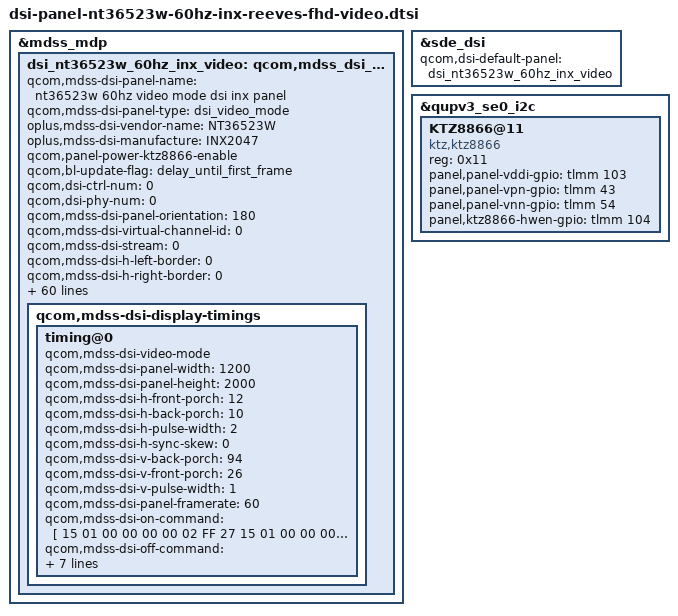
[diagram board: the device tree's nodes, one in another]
&mdss_mdp {
	dsi_nt36523w_60hz_inx_video: qcom,mdss_dsi_nt36523w_60hz_inx_video {
		qcom,mdss-dsi-panel-name =
			"nt36523w 60hz video mode dsi inx panel";
		qcom,mdss-dsi-panel-type = "dsi_video_mode";
		oplus,mdss-dsi-vendor-name = "NT36523W";
		oplus,mdss-dsi-manufacture = "INX2047";
		qcom,panel-power-ktz8866-enable;
		qcom,bl-update-flag = "delay_until_first_frame";

		qcom,dsi-ctrl-num = <0>;
		qcom,dsi-phy-num = <0>;
		qcom,mdss-dsi-panel-orientation = "180";
		qcom,mdss-dsi-virtual-channel-id = <0>;
		qcom,mdss-dsi-stream = <0>;
		qcom,mdss-dsi-h-left-border = <0>;
		qcom,mdss-dsi-h-right-border = <0>;
		qcom,mdss-dsi-v-top-border = <0>;
		qcom,mdss-dsi-v-bottom-border = <0>;
		qcom,mdss-dsi-bpp = <24>;
		qcom,mdss-dsi-color-order = "rgb_swap_rgb";
		qcom,mdss-dsi-underflow-color = <0xff>;
		qcom,mdss-dsi-border-color = <0>;
		qcom,mdss-dsi-h-sync-pulse = <0>;
		qcom,mdss-dsi-traffic-mode = "non_burst_sync_event";
		qcom,mdss-dsi-lane-map = "lane_map_0123";
		qcom,mdss-dsi-bllp-eof-power-mode;
		qcom,mdss-dsi-bllp-power-mode;
		qcom,mdss-dsi-tx-eot-append;
		qcom,mdss-dsi-lane-0-state;
		qcom,mdss-dsi-lane-1-state;
		qcom,mdss-dsi-lane-2-state;
		qcom,mdss-dsi-lane-3-state;
		qcom,mdss-dsi-dma-trigger = "trigger_sw";
		qcom,mdss-dsi-mdp-trigger = "none";
		qcom,mdss-dsi-lp11-init;
		qcom,mdss-dsi-incell-screen;
		qcom,mdss-dsi-bl-pmic-control-type = "bl_ctrl_external";
		qcom,mdss-dsi-reset-sequence = <0 10>, <1 10>, <0 10>, <1 10>;
		qcom,mdss-pan-physical-width-dimension = <135>;
		qcom,mdss-pan-physical-height-dimension = <226>;
		qcom,mdss-dsi-display-timings {
			timing@0 {
				qcom,mdss-dsi-video-mode;
				qcom,mdss-dsi-panel-width = <1200>;
				qcom,mdss-dsi-panel-height = <2000>;
				qcom,mdss-dsi-h-front-porch = <12>;
				qcom,mdss-dsi-h-back-porch = <10>;
				qcom,mdss-dsi-h-pulse-width = <2>;
				qcom,mdss-dsi-h-sync-skew = <0>;
				qcom,mdss-dsi-v-back-porch = <94>;
				qcom,mdss-dsi-v-front-porch = <26>;
				qcom,mdss-dsi-v-pulse-width = <1>;
				qcom,mdss-dsi-panel-framerate = <60>;
				qcom,mdss-dsi-on-command = [
					15 01 00 00 00 00 02 FF 27
					15 01 00 00 00 00 02 FB 01
					15 01 00 00 00 00 02 D0 31
					15 01 00 00 00 00 02 D1 88
					15 01 00 00 00 00 02 D2 30
					15 01 00 00 00 00 02 DE 43
					15 01 00 00 00 00 02 DF 02
					15 01 00 00 00 00 02 FF D0
					15 01 00 00 00 00 02 FB 01
					15 01 00 00 00 00 02 00 02
					15 01 00 00 00 00 02 FF 20
					15 01 00 00 00 00 02 FB 01
					15 01 00 00 00 00 02 05 D9
					15 01 00 00 00 00 02 0D 63
					15 01 00 00 00 00 02 0E 91
					15 01 00 00 00 00 02 0F 69
					15 01 00 00 00 00 02 07 7D
					15 01 00 00 00 00 02 08 5F
					15 01 00 00 00 00 02 0E 7D
					15 01 00 00 00 00 02 0F 7D
					15 01 00 00 00 00 02 95 F5
					15 01 00 00 00 00 02 96 F5
					15 01 00 00 00 00 02 9D 00
					15 01 00 00 00 00 02 9E 00
					15 01 00 00 00 00 02 44 51
					15 01 00 00 00 00 02 FF 20
					15 01 00 00 00 00 02 FB 01
					39 01 00 00 00 00 11 B0 00 00 00 1d 00 41 00 60 00 7a 00 91 00 a5 00 b8
					39 01 00 00 00 00 11 B1 00 c8 01 00 01 2a 01 6c 01 9f 01 ec 02 2b 02 2d
					39 01 00 00 00 00 11 B2 02 68 02 a9 02 d2 03 06 03 2a 03 53 03 5d 03 64
					39 01 00 00 00 00 0D B3 03 6a 03 76 03 80 03 8a 03 96 03 9a
					39 01 00 00 00 00 11 B4 00 00 00 1d 00 41 00 60 00 7a 00 91 00 a5 00 b8
					39 01 00 00 00 00 11 B5 00 c8 01 00 01 2a 01 6c 01 9f 01 ec 02 2b 02 2d
					39 01 00 00 00 00 11 B6 02 68 02 a9 02 d2 03 06 03 2a 03 53 03 5d 03 64
					39 01 00 00 00 00 0D B7 03 6a 03 76 03 80 03 8a 03 96 03 9a
					39 01 00 00 00 00 11 B8 00 00 00 1d 00 41 00 60 00 7a 00 91 00 a5 00 b8
					39 01 00 00 00 00 11 B9 00 c8 01 00 01 2a 01 6c 01 9f 01 ec 02 2b 02 2d
					39 01 00 00 00 00 11 BA 02 68 02 a9 02 d2 03 06 03 2a 03 53 03 5d 03 64
					39 01 00 00 00 00 0D BB 03 6a 03 76 03 80 03 8a 03 96 03 9a
					15 01 00 00 00 00 02 FF 21
					15 01 00 00 00 00 02 FB 01
					39 01 00 00 00 00 11 B0 00 00 00 1d 00 41 00 60 00 7a 00 91 00 a5 00 b8
					39 01 00 00 00 00 11 B1 00 c8 01 00 01 2a 01 6c 01 9f 01 ec 02 2b 02 2d
					39 01 00 00 00 00 11 B2 02 68 02 a9 02 d2 03 06 03 2a 03 53 03 61 03 74
					39 01 00 00 00 00 0D B3 03 8c 03 a3 03 c8 03 de 03 e6 03 e6
					39 01 00 00 00 00 11 B4 00 00 00 1d 00 41 00 60 00 7a 00 91 00 a5 00 b8
					39 01 00 00 00 00 11 B5 00 c8 01 00 01 2a 01 6c 01 9f 01 ec 02 2b 02 2d
					39 01 00 00 00 00 11 B6 02 68 02 a9 02 d2 03 06 03 2a 03 53 03 61 03 74
					39 01 00 00 00 00 0D B7 03 8c 03 a3 03 c8 03 de 03 e6 03 e6
					39 01 00 00 00 00 11 B8 00 00 00 1d 00 41 00 60 00 7a 00 91 00 a5 00 b8
					39 01 00 00 00 00 11 B9 00 c8 01 00 01 2a 01 6c 01 9f 01 ec 02 2b 02 2d
					39 01 00 00 00 00 11 BA 02 68 02 a9 02 d2 03 06 03 2a 03 53 03 61 03 74
					39 01 00 00 00 00 0D BB 03 8c 03 a3 03 c8 03 de 03 e6 03 e6
					15 01 00 00 00 00 02 FF 24
					15 01 00 00 00 00 02 FB 01
					15 01 00 00 00 00 02 91 44
					15 01 00 00 00 00 02 92 77
					15 01 00 00 00 00 02 93 1A
					15 01 00 00 00 00 02 94 40
					15 01 00 00 00 00 02 9A 08
					15 01 00 00 00 00 02 60 96
					15 01 00 00 00 00 02 61 D0
					15 01 00 00 00 00 02 63 70
					15 01 00 00 00 00 02 C2 C6
					15 01 00 00 00 00 02 9B 0F
					15 01 00 00 00 00 02 9A 08
					15 01 00 00 00 00 02 A5 00
					15 01 00 00 00 00 02 A6 41
					15 01 00 00 00 00 02 00 03
					15 01 00 00 00 00 02 01 03
					15 01 00 00 00 00 02 02 03
					15 01 00 00 00 00 02 03 03
					15 01 00 00 00 00 02 04 03
					15 01 00 00 00 00 02 05 03
					15 01 00 00 00 00 02 06 03
					15 01 00 00 00 00 02 07 03
					15 01 00 00 00 00 02 08 22
					15 01 00 00 00 00 02 09 08
					15 01 00 00 00 00 02 0A 05
					15 01 00 00 00 00 02 0B 1D
					15 01 00 00 00 00 02 0C 1C
					15 01 00 00 00 00 02 0D 11
					15 01 00 00 00 00 02 0E 10
					15 01 00 00 00 00 02 0F 0F
					15 01 00 00 00 00 02 10 0E
					15 01 00 00 00 00 02 11 0D
					15 01 00 00 00 00 02 12 0C
					15 01 00 00 00 00 02 13 04
					15 01 00 00 00 00 02 14 03
					15 01 00 00 00 00 02 15 03
					15 01 00 00 00 00 02 16 03
					15 01 00 00 00 00 02 17 03
					15 01 00 00 00 00 02 18 03
					15 01 00 00 00 00 02 19 03
					15 01 00 00 00 00 02 1A 03
					15 01 00 00 00 00 02 1B 03
					15 01 00 00 00 00 02 1C 03
					15 01 00 00 00 00 02 1D 03
					15 01 00 00 00 00 02 1E 22
					15 01 00 00 00 00 02 1F 08
					15 01 00 00 00 00 02 20 05
					15 01 00 00 00 00 02 21 1D
					15 01 00 00 00 00 02 22 1C
					15 01 00 00 00 00 02 23 11
					15 01 00 00 00 00 02 24 10
					15 01 00 00 00 00 02 25 0F
					15 01 00 00 00 00 02 26 0E
					15 01 00 00 00 00 02 27 0D
					15 01 00 00 00 00 02 28 0C
					15 01 00 00 00 00 02 29 04
					15 01 00 00 00 00 02 2A 03
					15 01 00 00 00 00 02 2B 03
					15 01 00 00 00 00 02 2F 05
					15 01 00 00 00 00 02 30 33
					15 01 00 00 00 00 02 31 40
					15 01 00 00 00 00 02 33 33
					15 01 00 00 00 00 02 34 05
					15 01 00 00 00 00 02 35 40
					15 01 00 00 00 00 02 37 55
					15 01 00 00 00 00 02 38 40
					15 01 00 00 00 00 02 39 00
					15 01 00 00 00 00 02 3A 51
					15 01 00 00 00 00 02 3B 3E
					15 01 00 00 00 00 02 3D 92
					15 01 00 00 00 00 02 AB 55
					15 01 00 00 00 00 02 AC 40
					15 01 00 00 00 00 02 3F 40
					15 01 00 00 00 00 02 43 40
					15 01 00 00 00 00 02 47 55
					15 01 00 00 00 00 02 4A 51
					15 01 00 00 00 00 02 4B 3E
					15 01 00 00 00 00 02 4C 91
					15 01 00 00 00 00 02 4D 21
					15 01 00 00 00 00 02 4E 43
					15 01 00 00 00 00 02 4F 65
					15 01 00 00 00 00 02 51 34
					15 01 00 00 00 00 02 52 12
					15 01 00 00 00 00 02 53 56
					39 01 00 00 00 00 03 55 84 04
					15 01 00 00 00 00 02 56 06
					15 01 00 00 00 00 02 58 21
					15 01 00 00 00 00 02 59 50
					15 01 00 00 00 00 02 5A 51
					15 01 00 00 00 00 02 5B 3E
					39 01 00 00 00 00 03 5E 00 0C
					15 01 00 00 00 00 02 5F 00
					15 01 00 00 00 00 02 7A FF
					15 01 00 00 00 00 02 7B FF
					15 01 00 00 00 00 02 7C 00
					15 01 00 00 00 00 02 7D 00
					15 01 00 00 00 00 02 7E 20
					15 01 00 00 00 00 02 7F 3C
					15 01 00 00 00 00 02 80 00
					15 01 00 00 00 00 02 81 00
					15 01 00 00 00 00 02 82 08
					15 01 00 00 00 00 02 97 02
					15 01 00 00 00 00 02 C5 10
					15 01 00 00 00 00 02 D7 55
					15 01 00 00 00 00 02 D8 55
					15 01 00 00 00 00 02 D9 23
					15 01 00 00 00 00 02 DA 05
					15 01 00 00 00 00 02 DB 01
					15 01 00 00 00 00 02 DC 77
					15 01 00 00 00 00 02 DD 55
					15 01 00 00 00 00 02 DE 27
					15 01 00 00 00 00 02 DF 01
					15 01 00 00 00 00 02 E0 77
					15 01 00 00 00 00 02 E1 01
					15 01 00 00 00 00 02 E2 77
					15 01 00 00 00 00 02 E3 01
					15 01 00 00 00 00 02 E4 77
					15 01 00 00 00 00 02 E5 01
					15 01 00 00 00 00 02 E6 77
					15 01 00 00 00 00 02 E7 00
					15 01 00 00 00 00 02 E8 00
					15 01 00 00 00 00 02 E9 01
					15 01 00 00 00 00 02 EA 77
					15 01 00 00 00 00 02 EB 01
					15 01 00 00 00 00 02 EE 77
					15 01 00 00 00 00 02 EF 01
					15 01 00 00 00 00 02 F0 77
					15 01 00 00 00 00 02 FF 25
					15 01 00 00 00 00 02 FB 01
					15 01 00 00 00 00 02 05 00
					15 01 00 00 00 00 02 F1 10
					15 01 00 00 00 00 02 1E 00
					15 01 00 00 00 00 02 1F 51
					15 01 00 00 00 00 02 20 3E
					15 01 00 00 00 00 02 25 00
					15 01 00 00 00 00 02 26 51
					15 01 00 00 00 00 02 27 3E
					15 01 00 00 00 00 02 3F 80
					15 01 00 00 00 00 02 40 00
					15 01 00 00 00 00 02 43 00
					15 01 00 00 00 00 02 44 51
					15 01 00 00 00 00 02 45 3E
					15 01 00 00 00 00 02 48 51
					15 01 00 00 00 00 02 49 3E
					15 01 00 00 00 00 02 5B 80
					15 01 00 00 00 00 02 5C 00
					15 01 00 00 00 00 02 5D 51
					15 01 00 00 00 00 02 5E 3E
					15 01 00 00 00 00 02 5F 51
					15 01 00 00 00 00 02 60 3E
					15 01 00 00 00 00 02 61 51
					15 01 00 00 00 00 02 62 3E
					15 01 00 00 00 00 02 68 0C
					15 01 00 00 00 00 02 FF 26
					15 01 00 00 00 00 02 FB 01
					15 01 00 00 00 00 02 00 A1
					15 01 00 00 00 00 02 02 31
					15 01 00 00 00 00 02 04 28
					15 01 00 00 00 00 02 06 30
					15 01 00 00 00 00 02 0C 13
					15 01 00 00 00 00 02 0D 0A
					15 01 00 00 00 00 02 0F 0A
					15 01 00 00 00 00 02 11 00
					15 01 00 00 00 00 02 12 50
					15 01 00 00 00 00 02 13 51
					15 01 00 00 00 00 02 14 65
					15 01 00 00 00 00 02 15 00
					15 01 00 00 00 00 02 16 10
					15 01 00 00 00 00 02 17 A0
					15 01 00 00 00 00 02 18 86
					15 01 00 00 00 00 02 22 00
					15 01 00 00 00 00 02 23 00
					15 01 00 00 00 00 02 19 0A
					15 01 00 00 00 00 02 1A A0
					15 01 00 00 00 00 02 1B 0A
					15 01 00 00 00 00 02 1C 00
					15 01 00 00 00 00 02 2A 0A
					15 01 00 00 00 00 02 2B A0
					15 01 00 00 00 00 02 1D 00
					15 01 00 00 00 00 02 1E 77
					15 01 00 00 00 00 02 1F 77
					15 01 00 00 00 00 02 2F 04
					15 01 00 00 00 00 02 30 77
					15 01 00 00 00 00 02 31 04
					15 01 00 00 00 00 02 32 97
					15 01 00 00 00 00 02 33 89
					15 01 00 00 00 00 02 34 67
					15 01 00 00 00 00 02 39 0C
					15 01 00 00 00 00 02 3A 74
					15 01 00 00 00 00 02 3B 06
					15 01 00 00 00 00 02 C8 04
					15 01 00 00 00 00 02 C9 8B
					15 01 00 00 00 00 02 CA 4E
					15 01 00 00 00 00 02 CB 00
					15 01 00 00 00 00 02 A9 50
					15 01 00 00 00 00 02 AA 4F
					15 01 00 00 00 00 02 AB 4E
					15 01 00 00 00 00 02 AC 4D
					15 01 00 00 00 00 02 AD 4C
					15 01 00 00 00 00 02 AE 4B
					15 01 00 00 00 00 02 AF 4A
					15 01 00 00 00 00 02 B0 49
					15 01 00 00 00 00 02 B1 47
					15 01 00 00 00 00 02 B2 45
					15 01 00 00 00 00 02 FF 27
					15 01 00 00 00 00 02 C0 18
					15 01 00 00 00 00 02 C1 00
					15 01 00 00 00 00 02 C2 00
					15 01 00 00 00 00 02 56 06
					15 01 00 00 00 00 02 58 80
					15 01 00 00 00 00 02 59 52
					15 01 00 00 00 00 02 5A 00
					15 01 00 00 00 00 02 5B 14
					15 01 00 00 00 00 02 5C 00
					15 01 00 00 00 00 02 5D 00
					15 01 00 00 00 00 02 5E 20
					15 01 00 00 00 00 02 5F 10
					15 01 00 00 00 00 02 60 00
					15 01 00 00 00 00 02 61 1B
					15 01 00 00 00 00 02 62 00
					15 01 00 00 00 00 02 63 01
					15 01 00 00 00 00 02 64 23
					15 01 00 00 00 00 02 65 1A
					15 01 00 00 00 00 02 66 00
					15 01 00 00 00 00 02 67 01
					15 01 00 00 00 00 02 68 23
					15 01 00 00 00 00 02 00 00
					15 01 00 00 00 00 02 C3 00
					15 01 00 00 00 00 02 98 01
					15 01 00 00 00 00 02 B4 03
					15 01 00 00 00 00 02 9B BE
					15 01 00 00 00 00 02 AB 14
					15 01 00 00 00 00 02 BC 08
					15 01 00 00 00 00 02 BD 28
					15 01 00 00 00 00 02 FF 2A
					15 01 00 00 00 00 02 FB 01
					15 01 00 00 00 00 02 22 2F
					15 01 00 00 00 00 02 23 08
					15 01 00 00 00 00 02 24 00
					15 01 00 00 00 00 02 25 76
					15 01 00 00 00 00 02 26 F8
					15 01 00 00 00 00 02 27 00
					15 01 00 00 00 00 02 28 1A
					15 01 00 00 00 00 02 29 00
					15 01 00 00 00 00 02 2A 1A
					15 01 00 00 00 00 02 2B 00
					15 01 00 00 00 00 02 2D 1A
					15 01 00 00 00 00 02 64 96
					15 01 00 00 00 00 02 65 00
					15 01 00 00 00 00 02 66 00
					15 01 00 00 00 00 02 6A 96
					15 01 00 00 00 00 02 6B 00
					15 01 00 00 00 00 02 6C 00
					15 01 00 00 00 00 02 70 92
					15 01 00 00 00 00 02 71 00
					15 01 00 00 00 00 02 72 00
					15 01 00 00 00 00 02 A2 33
					15 01 00 00 00 00 02 A3 30
					15 01 00 00 00 00 02 A4 C0
					15 01 00 00 00 00 02 E8 00
					15 01 00 00 00 00 02 97 3C
					15 01 00 00 00 00 02 98 02
					15 01 00 00 00 00 02 99 95
					15 01 00 00 00 00 02 9A 06
					15 01 00 00 00 00 02 9B 00
					15 01 00 00 00 00 02 9C 0B
					15 01 00 00 00 00 02 9D 0A
					15 01 00 00 00 00 02 9E 90
					15 01 00 00 00 00 02 FF 25
					15 01 00 00 00 00 02 13 02
					15 01 00 00 00 00 02 14 F2
					15 01 00 00 00 00 02 FF 25
					15 01 00 00 00 00 02 FB 01
					15 01 00 00 00 00 02 17 CF
					15 01 00 00 00 00 02 19 0F
					15 01 00 00 00 00 02 1B 5B
					15 01 00 00 00 00 02 FF 26
					15 01 00 00 00 00 02 FB 01
					15 01 00 00 00 00 02 00 81
					15 01 00 00 00 00 02 01 70
					15 01 00 00 00 00 02 40 76
					15 01 00 00 00 00 02 41 76
					15 01 00 00 00 00 02 42 76
					15 01 00 00 00 00 02 45 04
					15 01 00 00 00 00 02 46 76
					15 01 00 00 00 00 02 47 04
					15 01 00 00 00 00 02 48 83
					15 01 00 00 00 00 02 4D 51
					15 01 00 00 00 00 02 4E 3E
					15 01 00 00 00 00 02 4F 51
					15 01 00 00 00 00 02 50 3E
					15 01 00 00 00 00 02 51 51
					15 01 00 00 00 00 02 52 3E
					15 01 00 00 00 00 02 56 51
					15 01 00 00 00 00 02 58 3E
					15 01 00 00 00 00 02 5B 51
					15 01 00 00 00 00 02 5C 3E
					15 01 00 00 00 00 02 64 51
					15 01 00 00 00 00 02 65 3E
					15 01 00 00 00 00 02 6E 51
					15 01 00 00 00 00 02 6F 3E
					15 01 00 00 00 00 02 70 51
					15 01 00 00 00 00 02 71 3E
					15 01 00 00 00 00 02 72 51
					15 01 00 00 00 00 02 73 3E
					15 01 00 00 00 00 02 8B 50
					15 01 00 00 00 00 02 8C 7C
					15 01 00 00 00 00 02 92 50
					15 01 00 00 00 00 02 93 10
					15 01 00 00 00 00 02 94 10
					15 01 00 00 00 00 02 96 10
					15 01 00 00 00 00 02 C9 80
					15 01 00 00 00 00 02 FF 2A
					15 01 00 00 00 00 02 FB 01
					15 01 00 00 00 00 02 01 01
					15 01 00 00 00 00 02 02 11
					15 01 00 00 00 00 02 05 01
					15 01 00 00 00 00 02 06 76
					15 01 00 00 00 00 02 08 01
					15 01 00 00 00 00 02 09 76
					15 01 00 00 00 00 02 0C 01
					15 01 00 00 00 00 02 0D 76
					15 01 00 00 00 00 02 FF F0
					15 01 00 00 00 00 02 FB 01
					15 01 00 00 00 00 02 3A 08
					15 01 00 00 00 00 02 FF D0
					15 01 00 00 00 00 02 FB 01
					15 01 00 00 00 00 02 02 AF
					15 01 00 00 00 00 02 09 FF
					15 01 00 00 00 00 02 FF 23
					15 01 00 00 00 00 02 FB 01
					15 01 00 00 00 00 02 00 68
					15 01 00 00 00 00 02 07 00
					15 01 00 00 00 00 02 08 01
					15 01 00 00 00 00 02 09 90
					15 01 00 00 00 00 02 FF 23
					15 01 00 00 00 00 02 FB 01
					15 01 00 00 00 00 02 10 0C
					15 01 00 00 00 00 02 11 02
					15 01 00 00 00 00 02 12 80
					15 01 00 00 00 00 02 15 83
					15 01 00 00 00 00 02 16 0C
					15 01 00 00 00 00 02 19 00
					15 01 00 00 00 00 02 1A 04
					15 01 00 00 00 00 02 1B 08
					15 01 00 00 00 00 02 1C 0C
					15 01 00 00 00 00 02 1D 10
					15 01 00 00 00 00 02 1E 14
					15 01 00 00 00 00 02 1F 18
					15 01 00 00 00 00 02 20 1C
					15 01 00 00 00 00 02 21 20
					15 01 00 00 00 00 02 22 24
					15 01 00 00 00 00 02 23 28
					15 01 00 00 00 00 02 24 2C
					15 01 00 00 00 00 02 25 30
					15 01 00 00 00 00 02 26 34
					15 01 00 00 00 00 02 27 38
					15 01 00 00 00 00 02 28 3C
					15 01 00 00 00 00 02 29 20
					15 01 00 00 00 00 02 2A 20
					15 01 00 00 00 00 02 2B 30
					15 01 00 00 00 00 02 30 FF
					15 01 00 00 00 00 02 31 FC
					15 01 00 00 00 00 02 32 FA
					15 01 00 00 00 00 02 33 F4
					15 01 00 00 00 00 02 34 F2
					15 01 00 00 00 00 02 35 F0
					15 01 00 00 00 00 02 36 EF
					15 01 00 00 00 00 02 37 EC
					15 01 00 00 00 00 02 38 EC
					15 01 00 00 00 00 02 39 E9
					15 01 00 00 00 00 02 3A E9
					15 01 00 00 00 00 02 3B E8
					15 01 00 00 00 00 02 3D E7
					15 01 00 00 00 00 02 3F E6
					15 01 00 00 00 00 02 40 E5
					15 01 00 00 00 00 02 41 E3
					15 01 00 00 00 00 02 58 FF
					15 01 00 00 00 00 02 59 FB
					15 01 00 00 00 00 02 5A EE
					15 01 00 00 00 00 02 5B E8
					15 01 00 00 00 00 02 5C E3
					15 01 00 00 00 00 02 5D DE
					15 01 00 00 00 00 02 5E D6
					15 01 00 00 00 00 02 5F D4
					15 01 00 00 00 00 02 60 D2
					15 01 00 00 00 00 02 61 D0
					15 01 00 00 00 00 02 62 CC
					15 01 00 00 00 00 02 63 CC
					15 01 00 00 00 00 02 64 CA
					15 01 00 00 00 00 02 65 C8
					15 01 00 00 00 00 02 66 C4
					15 01 00 00 00 00 02 67 C0
					15 01 00 00 00 00 02 FF 20
					15 01 00 00 00 00 02 FB 01
					39 01 00 00 00 00 0D C3 27 26 1E 20 19 18 17 16 15 13 07 03
					15 01 00 00 00 00 02 FF 10
					15 01 00 00 00 00 02 B9 01
					15 01 00 00 00 00 02 FF 20
					15 01 00 00 00 00 02 18 40
					15 01 00 00 00 00 02 FF 10
					15 01 00 00 00 00 02 B9 02
					15 01 00 00 00 00 02 FF 10
					15 01 00 00 00 00 02 FB 01
					15 01 00 00 00 00 02 B0 01
					15 01 00 00 00 00 02 35 00
					15 01 00 00 00 00 02 55 00
					39 01 00 00 00 00 03 68 05 01
					39 01 00 00 00 00 06 3B 03 5F 1A 04 04
					05 01 00 00 64 00 02 11 00
					05 01 00 00 00 00 02 29 00];
				qcom,mdss-dsi-off-command = [
					05 01 00 00 14 00 02 28 00
					05 01 00 00 78 00 02 10 00];
				qcom,mdss-dsi-on-command-state = "dsi_lp_mode";
				qcom,mdss-dsi-off-command-state = "dsi_hs_mode";
			};
		};
	};
};

&dsi_nt36523w_60hz_inx_video {
	qcom,mdss-dsi-bl-pmic-control-type = "bl_ctrl_external";
	qcom,mdss-dsi-bl-min-level = <1>;
	qcom,mdss-dsi-bl-normal-max-level = <2047>;
	qcom,mdss-dsi-bl-max-level = <2047>;
	qcom,mdss-brightness-max-level = <2047>;
	qcom,mdss-brightness-min-level = <1>;
    qcom,mdss-brightness-normal-max-level = <2047>;
	qcom,mdss-brightness-default-level = <1600>;
	qcom,platform-reset-gpio = <&tlmm 82 0>;

	oplus,oplus-panel-power-ctl;
	oplus,panel-shutdown-power-set-flag;
	/* close TP gesture sequence */
	oplus,panel-on-power-sequence = "set_bias", "set_reset", "tp_load_fw", "set_end";
	oplus,panel-off-power-sequence = "set_bias", "set_reset_sel", "set_end";
	oplus,panel-shutdown-power-sequence = "set_reset", "set_bias", "set_end";
	/* open TP gesture sequence */
	oplus,panel-gesture-on-power-sequence = "set_bias", "set_reset", "tp_load_fw", "set_end";
	oplus,panel-gesture-off-power-sequence = "set_reset_sel", "set_end";
	oplus,panel-gesture-shutdown-power-sequence = "set_reset", "set_bias", "set_end";
	/* mdelay:<on_behind_mdelay off_behind_mdelay gesture_on_behind_mdelay gesture_off_behind_mdelay> */
	oplus,panel-power-reset-mdelay = <0 3 0 3>;
	oplus,panel-power-regulator-mdelay = <0 70 0 0>;
	oplus,panel-power-pinctrl-mdelay = <0 0 0 70>;
	oplus,panel-on-mdelay-bl = <30>;
};

&dsi_nt36523w_60hz_inx_video {
	qcom,esd-check-enabled;
	qcom,mdss-dsi-panel-status-check-mode = "check_esd_gpio";
	qcom,panel-master-esd-gpio = <&tlmm 81 0>;
	qcom,panel-slaves-esd-gpio = <&tlmm 97 0>;
	qcom,dsi-select-clocks = "mux_byte_clk0", "mux_pixel_clk0";
	qcom,mdss-dsi-display-timings {
		timing@0 {
			qcom,mdss-dsi-panel-phy-timings = [00 20 08 08 18 23 08
					08 08 02 04 00 1B 0D];
			qcom,display-topology = <1 0 1>;
			qcom,default-topology-index = <0>;
		};
	};
};

&sde_dsi {
	qcom,dsi-default-panel = <&dsi_nt36523w_60hz_inx_video>;
};

&qupv3_se0_i2c {
	KTZ8866@11 {
		compatible = "ktz,ktz8866";
		reg = <0x11>;
		panel,panel-vddi-gpio = <&tlmm 103 0>;
		panel,panel-vpn-gpio = <&tlmm 43 0>;
		panel,panel-vnn-gpio = <&tlmm 54 0>;
		panel,ktz8866-hwen-gpio = <&tlmm 104 0>;
	};
};
